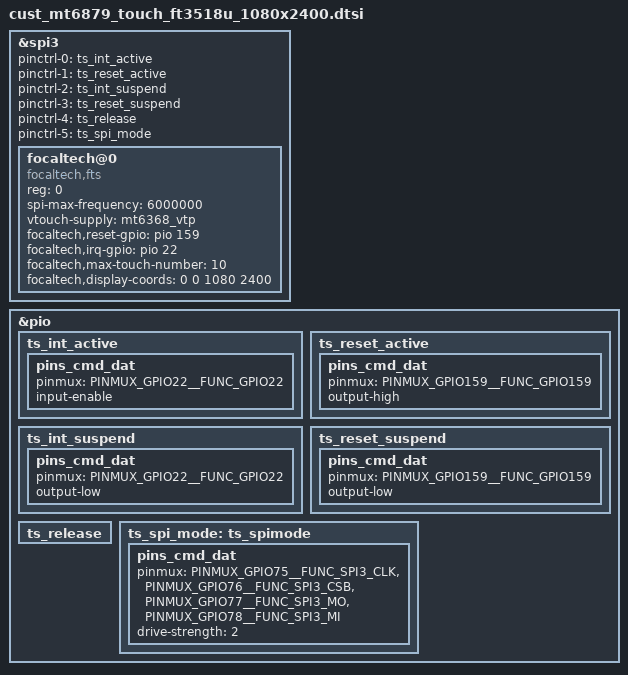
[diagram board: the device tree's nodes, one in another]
// SPDX-License-Identifier: (GPL-2.0 OR MIT)
/*
 * Copyright (C) 2020 MediaTek Inc.
 */

/*TOUCH begin*/
&spi3 {
	status = "okay";
	#address-cells = <1>;
	#size-cells = <0>;
	pinctrl-names = "pmx_ts_int_active", "pmx_ts_rst_active",
		"pmx_ts_int_suspend", "pmx_ts_rst_suspend",
		"pmx_ts_release", "ft3518u_spi_mode";
	pinctrl-0 = <&ts_int_active>;
	pinctrl-1 = <&ts_reset_active>;
	pinctrl-2 = <&ts_int_suspend>;
	pinctrl-3 = <&ts_reset_suspend>;
	pinctrl-4 = <&ts_release>;
	pinctrl-5 = <&ts_spi_mode>;

	focaltech@0 {
		status = "okay";
		compatible = "focaltech,fts";
		reg = <0>;
		spi-max-frequency = <6000000>;
		vtouch-supply = <&mt6368_vtp>;
		focaltech,reset-gpio = <&pio 159 0x0>;
		focaltech,irq-gpio = <&pio 22 0x0>;
		focaltech,max-touch-number = <10>;
		focaltech,display-coords = <0 0 1080 2400>;
	};

};

&pio {
	ts_int_active: ts_int_active {
		pins_cmd_dat {
			pinmux = <PINMUX_GPIO22__FUNC_GPIO22>;
			input-enable;
		};
	};

	ts_reset_active: ts_reset_active {
		pins_cmd_dat {
			pinmux = <PINMUX_GPIO159__FUNC_GPIO159>;
			output-high;
		};
	};

	ts_int_suspend: ts_int_suspend {
		pins_cmd_dat {
			pinmux = <PINMUX_GPIO22__FUNC_GPIO22>;
			output-low;
		};
	};

	ts_reset_suspend: ts_reset_suspend {
		pins_cmd_dat {
			pinmux = <PINMUX_GPIO159__FUNC_GPIO159>;
			output-low;
		};
	};

	ts_release: ts_release {
	};

	ts_spi_mode: ts_spimode {
		pins_cmd_dat {
			pinmux = <PINMUX_GPIO75__FUNC_SPI3_CLK>,
				<PINMUX_GPIO76__FUNC_SPI3_CSB>,
				<PINMUX_GPIO77__FUNC_SPI3_MO>,
				<PINMUX_GPIO78__FUNC_SPI3_MI>;
			drive-strength = <2>;
		};
	};

};
/*TOUCH end*/
